# WKUP_VTM0_MMR_VBUSP_CFG1 register map
Vendor: Texas Instruments
Peripheral module from a debugger description file (folder J7VCL).
Registers are 32-bit, access not given, reset 0x0 unless marked. A register's access mark holds for its fields unless they carry their own. Offsets are as the file gives them; lines under a group give offsets from that group; [hi:lo] are bit positions; {n}, {i} and the like mark numbered series; 'fields as' and 'values as' point back to an identical list; <NAME> marks a mode.

## WKUP_VTM0_MMR_VBUSP_CFG1
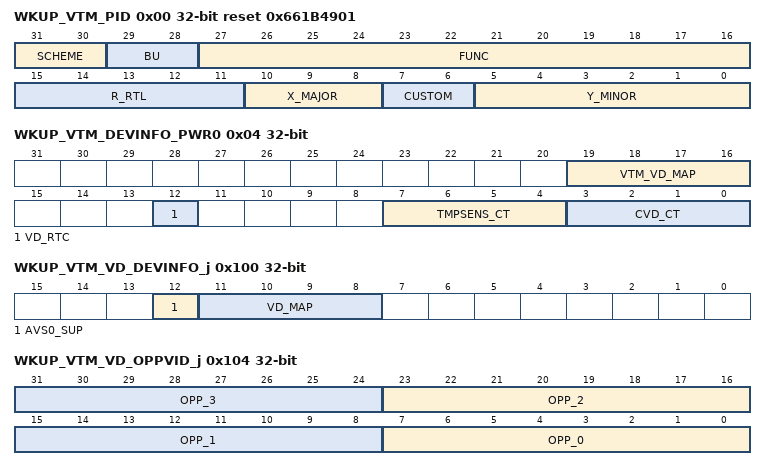
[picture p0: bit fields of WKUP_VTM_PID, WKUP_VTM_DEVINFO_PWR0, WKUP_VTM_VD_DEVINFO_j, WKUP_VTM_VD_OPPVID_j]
0x00 WKUP_VTM_PID ro reset 0x661B4901 — VTM Peripheral Identification Register
  [31:30] SCHEME — PID scheme
  [29:28] BU
  [27:16] FUNC — Module functional identifier
  [15:11] R_RTL — RTL revision number
  [10:8] X_MAJOR — Major revision number
  [7:6] CUSTOM — Custom revision number
  [5:0] Y_MINOR — Minor revision number
0x04 WKUP_VTM_DEVINFO_PWR0 ro reset not defined — Device specific voltage domain and temp sensor information register.
  [19:16] VTM_VD_MAP — Core voltage domain, cVD, global mapping 4-bit code, in the context of this SoC.
  [12] VD_RTC — RTC voltage domain presence.
  [7:4] TMPSENS_CT — Number of temperature sensors associated with this VTM.
  [3:0] CVD_CT — Number of core voltage domains in device.
0x100 WKUP_VTM_VD_DEVINFO_j access per field reset not defined — Voltage domain a information register. The default reset values will not be necessarily overwritten. The write capability in the MMR is for having the option to debug and have software driven adjustments if necessary. Offset = 100h + (j * 20h); where j = 0h to 7h
  [12] AVS0_SUP rw — Indicates VD0 AVS class0 support.
  [11:8] VD_MAP ro — Indicates the core voltage domain mapping of VTM VD.
0x104 WKUP_VTM_VD_OPPVID_j rw reset not defined — Voltage domain a VID actual code used as reference by Firmware to set the various voltage domain supply voltages. Reset defaults are sourced from efuse for each OPP. The default reset values will not be necessarily overwritten. The write capability in the MMR is for having the option to debug and have software driven adjustments if necessary. Offset = 104h + (j * 20h); where j = 0h to 7h
  [8n+7:8n] OPP_{n} (n=0..3) — OPP {n} default VID.
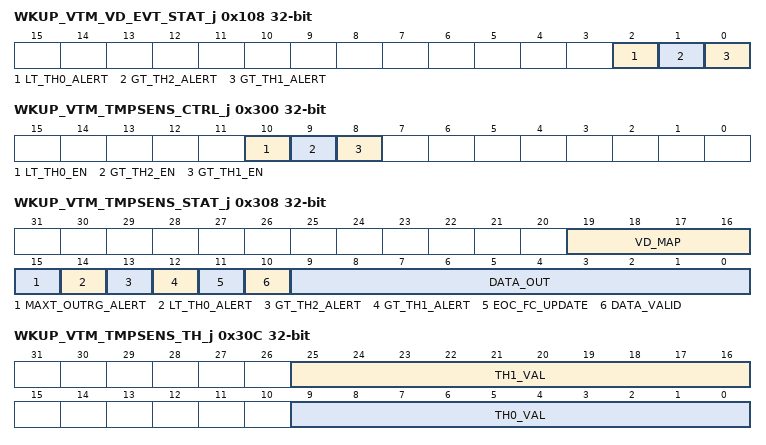
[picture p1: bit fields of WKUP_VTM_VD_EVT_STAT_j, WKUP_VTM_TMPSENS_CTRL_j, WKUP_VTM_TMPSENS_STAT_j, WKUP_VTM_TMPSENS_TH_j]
0x108 WKUP_VTM_VD_EVT_STAT_j ro reset not defined — Voltage domain a event and control status register. Offset = 108h + (j * 20h); where j = 0h to 7h
  [2] LT_TH0_ALERT — This bit reflects the status of the TH0 undertemp alert resulting from the AND of all the similar alerts produced by the temp sensors selected by VTM_VD[a]_EVT_SEL_SET.tsens_evt_sel.
  [1] GT_TH2_ALERT — This bit reflects the status of the merged temperature alert resulting from the combination of all the similar alerts produced by the temp-monitors selected as showed in field VTM_VD[a]_EVT_SEL_SET.tsens_evt_sel.
  [0] GT_TH1_ALERT — This bit reflects the status of the merged temperature alert resulting from the OR of all the similar alerts produced by the temp-monitors selected as showed in field VTM_VD[a]_EVT_SEL_SET.tsens_evt_sel.
0x10C WKUP_VTM_VD_EVT_SEL_SET_j — Voltage domain a event select and control set register. NOTE: This MMR and the companion MMR VTM_VD[a]_EVT_SEL_CLR are linked, which means that they are in fact a single common MMR, with 2 different write addresses/mechanisms, and thus the single common MMR updates with the writes to either MMR and reads to either of these 2 MMRs read the same content. Offset = 10Ch + (j * 20h); where j = 0h to 7h
  [23:16] TSENS_EVT_SEL — In this field we select which of the event contributions of the (access RW1S)
0x110 WKUP_VTM_VD_EVT_SEL_CLR_j — Voltage domain a event select and control clear register. NOTE: This MMR and the companion MMR VTM_VD[a]_EVT_SEL_SET are linked, which means that they are in fact a single common MMR, with 2 different write addresses/mechanisms, and thus the single common MMR updates with the writes to either MMR and reads to either of these 2 MMRs read the same content. Offset = 110h + (j * 20h); where j = 0h to 7h
  [23:16] TSENS_EVT_SEL — In this field we select which of the event contributions of the 8-maximum possible temp-monitors controlled by this VTM will contribute to generate the merged event/alerts of this VD. (access RW1C)
0x204 WKUP_VTM_GT_TH1_INT_RAW_STAT_SET — Interrupt RAW event status and set MMR for interrupt GT_TH1 for each voltage domain. NOTE: This MMR and the companion MMR, are fully linked for write operation, but partially linked for reads, which means that they are in fact a single common MMR, with 2 different write addresses/mechanisms, and thus the single common MMR updates with the writes to either MMR. However the reads to these 2 MMRs don't yield the same read data. Reads to *_INT_RAW_STAT_SET return the full 'raw' events contents of the common linked MMR, whereas reads to MMR *_INT_EN_STAT_CLR will yield the masked-content of the linked MMR. The mask for the read is defined by the contents of the related MMR *_INT_EN_SET/CLR.
  [7:0] INT_VD — Interrupt pending bit set for gt_th1_int from VD[7:0]. (access RW1S)
0x208 WKUP_VTM_GT_TH1_INT_EN_STAT_CLR — Enabled interrupt event status and clear MMR for interrupt GT_TH1 per voltage domain. NOTE: This MMR and the companion MMR, are fully linked for write operation, but partially linked for reads, which means that they are in fact a single common MMR, with 2 different write addresses/mechanisms, and thus the single common MMR updates with the writes to either MMR. However the reads to these 2 MMRs don't yield the same read data. Reads to *_INT_RAW_STAT_SET return the full 'raw' events contents of the common linked MMR, whereas reads to MMR *_INT_EN_STAT_CLR will yield the masked-content of the linked MMR. The mask for the read is defined by the contents of the related MMR *_INT_EN_SET/CLR.
  [7:0] INT_VD — Interrupt masked pending bit for gt_th1_int from VD[7:0]. (access RW1C)
0x214 WKUP_VTM_GT_TH1_INT_EN_SET — Enable set MMR for interrupt GT_TH1 for each voltage domain. NOTE: This MMR and the companion MMR, are linked, which means that they are in fact a single common MMR, with 2 different write addresses/mechanisms, and thus the single common MMR updates with the writes to either MMR and reads to either of these 2 MMRs read the same content.
  [7:0] INT_VD — Interrupt enable bit for gt_th1_int from VD[7:0]. (access RW1S)
0x218 WKUP_VTM_GT_TH1_INT_EN_CLR — Enable clear MMR for interrupt GT_TH1 for each voltage domain. NOTE: This MMR and the companion MMR, are linked, which means that they are in fact a single common MMR, with 2 different write addresses/mechanisms, and thus the single common MMR updates with the writes to either MMR and reads to either of these 2 MMRs read the same content.
  [7:0] INT_VD — Interrupt enable bit for gt_th1_int from VD[7:0]. (access RW1C)
0x224 WKUP_VTM_GT_TH2_INT_RAW_STAT_SET — Interrupt RAW event status and set MMR for interrupt GT_TH2 for each voltage domain. NOTE: This MMR and the companion MMR, are fully linked for write operation, but partially linked for reads, which means that they are in fact a single common MMR, with 2 different write addresses/mechanisms, and thus the single common MMR updates with the writes to either MMR. However the reads to these 2 MMRs don't yield the same read data. Reads to *_INT_RAW_STAT_SET return the full 'raw' events contents of the common linked MMR, whereas reads to MMR *_INT_EN_STAT_CLR will yield the masked-content of the linked MMR. The mask for the read is defined by the contents of the related MMR *_INT_EN_SET/CLR.
  [7:0] INT_VD — Interrupt pending bit set for gt_th2_int from VD[7:0]. (access RW1S)
0x228 WKUP_VTM_GT_TH2_INT_EN_STAT_CLR — Enabled interrupt event status and clear MMR for interrupt GT_TH2 per voltage domain. NOTE: This MMR and the companion MMR, are fully linked for write operation, but partially linked for reads, which means that they are in fact a single common MMR, with 2 different write addresses/mechanisms, and thus the single common MMR updates with the writes to either MMR. However the reads to these 2 MMRs don't yield the same read data. Reads to *_INT_RAW_STAT_SET return the full 'raw' events contents of the common linked MMR, whereas reads to MMR *_INT_EN_STAT_CLR will yield the masked-content of the linked MMR. The mask for the read is defined by the contents of the related MMR *_INT_EN_SET/CLR.
  [7:0] INT_VD — Interrupt enabled pending bit for gt_th2_int from VD[7:0]. (access RW1C)
0x234 WKUP_VTM_GT_TH2_INT_EN_SET — Enable set MMR for interrupt GT_TH2 for each voltage domain. NOTE: This MMR and the companion MMR, are linked, which means that they are in fact a single common MMR, with 2 different write addresses/mechanisms, and thus the single common MMR updates with the writes to either MMR and reads to either of these 2 MMRs read the same content.
  [7:0] INT_VD — Interrupt enable bit for gt_th2_int from VD[7:0]. (access RW1S)
0x238 WKUP_VTM_GT_TH2_INT_EN_CLR — Enable clear MMR for interrupt GT_TH2 for each voltage domain. NOTE: This MMR and the companion MMR, are linked, which means that they are in fact a single common MMR, with 2 different write addresses/mechanisms, and thus the single common MMR updates with the writes to either MMR and reads to either of these 2 MMRs read the same content.
  [7:0] INT_VD — Interrupt enable bit for gt_th2_int from VD[7:0]. (access RW1C)
0x244 WKUP_VTM_LT_TH0_INT_RAW_STAT_SET — Interrupt RAW event status and set MMR for interrupt LT_TH0 for each voltage domain. NOTE: This MMR and the companion MMR, are fully linked for write operation, but partially linked for reads, which means that they are in fact a single common MMR, with 2 different write addresses/mechanisms, and thus the single common MMR updates with the writes to either MMR. However the reads to these 2 MMRs don't yield the same read data. Reads to *_INT_RAW_STAT_SET return the full 'raw' events contents of the common linked MMR, whereas reads to MMR *_INT_EN_STAT_CLR will yield the masked-content of the linked MMR. The mask for the read is defined by the contents of the related MMR *_INT_EN_SET/CLR.
  [7:0] INT_VD — Interrupt pending bit set for lt_th0_int from VD[7:0]. (access RW1S)
0x248 WKUP_VTM_LT_TH0_INT_EN_STAT_CLR — Enabled interrupt event status and clear MMR for interrupt LT_TH0 per voltage domain. NOTE: This MMR and the companion MMR, are fully linked for write operation, but partially linked for reads, which means that they are in fact a single common MMR, with 2 different write addresses/mechanisms, and thus the single common MMR updates with the writes to either MMR. However the reads to these 2 MMRs don't yield the same read data. Reads to *_INT_RAW_STAT_SET return the full 'raw' events contents of the common linked MMR, whereas reads to MMR *_INT_EN_STAT_CLR will yield the masked-content of the linked MMR. The mask for the read is defined by the contents of the related MMR *_INT_EN_SET/CLR.
  [7:0] INT_VD — Interrupt enabled pending status bit for lt_th0_int from VD[7:0]. (access RW1C)
0x254 WKUP_VTM_LT_TH0_INT_EN_SET — Enable set MMR for interrupt LT_TH0 for each voltage domain. NOTE: This MMR and the companion MMR, are linked, which means that they are in fact a single common MMR, with 2 different write addresses/mechanisms, and thus the single common MMR updates with the writes to either MMR and reads to either of these 2 MMRs read the same content.
  [7:0] INT_VD — Interrupt enable bit for lt_th0_int from VD[7:0]. (access RW1S)
0x258 WKUP_VTM_LT_TH0_INT_EN_CLR — Enable clear MMR for interrupt LT_TH0 for each voltage domain. NOTE: This MMR and the companion MMR, are linked, which means that they are in fact a single common MMR, with 2 different write addresses/mechanisms, and thus the single common MMR updates with the writes to either MMR and reads to either of these 2 MMRs read the same content.
  [7:0] INT_VD — Interrupt enable bit for lt_th0_int from VD[7:0]. (access RW1C)
0x300 WKUP_VTM_TMPSENS_CTRL_j rw — Temperature Sensor Band-gap control register for sensor a. Offset = 300h + (j * 20h); where j = 0h to 7h
  [10] LT_TH0_EN — Enable under-threshold0 event.
  [9] GT_TH2_EN — Enable over-threshold2 event.
  [8] GT_TH1_EN — Enable over-threshold1 event.
0x308 WKUP_VTM_TMPSENS_STAT_j ro (reset mask 0x7800) — Temperature Sensor Band-gap Status register for sensor a. Offset = 308h + (j * 20h); where j = 0h to 7h
  [19:16] VD_MAP — Indicates the core voltage domain placement of the temp sensor.
  [15] MAXT_OUTRG_ALERT — This bit will be driven to a level 1 for a given temperature monitor if it has its corresponding bit maxt_outrg_en = 1, and the temperature reading is reporting to be outside the max temperature supported, temp &gt; programmed value.
  [14] LT_TH0_ALERT — This field reflects the status of the lt_th0_alert comparator result.
  [13] GT_TH2_ALERT — This field reflects the status of the gt_th2_alert comparator result.
  [12] GT_TH1_ALERT — This field reflects the status of the gt_th1_alert comparator result.
  [11] EOC_FC_UPDATE — First time end of conversion.
  [10] DATA_VALID — Data_valid signal value from sensor: ADC End of Conversion.
  [9:0] DATA_OUT — Data_out signal value from sensor: Temperature data from the ADC in monitor.
0x30C WKUP_VTM_TMPSENS_TH_j rw — Temperature Sensor Band-gap Threshold register for sensor a. Offset = 30Ch + (j * 20h); where j = 0h to 7h
  [25:16] TH1_VAL — Threshold point-1, thpt1, temp-value.
  [9:0] TH0_VAL — Threshold point-0, thpt0, temp-value.
0x310 WKUP_VTM_TMPSENS_TH2_j rw — Temperature Sensor Band-gap Threshold register 2 for sensor a. Offset = 310h + (j * 20h); where j = 0h to 7h
  [9:0] TH2_VAL — Threshold point-2, thpt2, temp-value.
